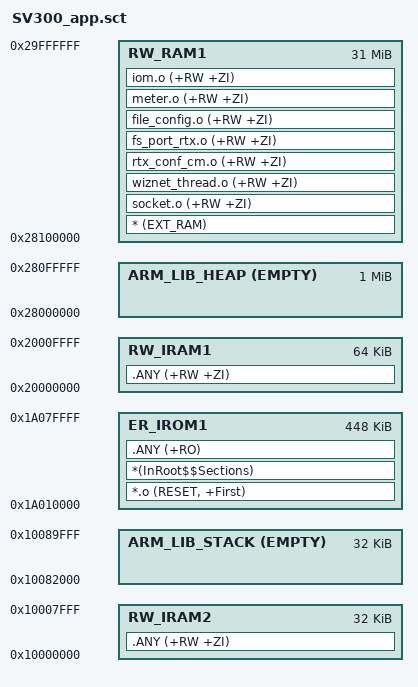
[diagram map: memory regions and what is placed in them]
;******************************************************************
;* LPC4337 linker scatter file (running code from internal FLASH) *
;******************************************************************

LR_IROM1 0x1A010000 0x70000
{
   ER_IROM1 0x1A010000 0x70000
   {
      *.o (RESET, +First)
      *(InRoot$$Sections)
      .ANY (+RO)
   }
   
   RW_IRAM1 0x20000000 0x10000
   { 
      .ANY (+RW +ZI)
   }
   
   RW_IRAM2 0x10000000 0x8000
   { 
      .ANY (+RW +ZI)
   }

   ARM_LIB_STACK 0x1008A000 EMPTY -0x8000
   {
   }
   
   ARM_LIB_HEAP 0x28000000 EMPTY 0x100000
   {
   }
   
   RW_RAM1 0x28100000 0x1f00000  {
      * (EXT_RAM)
      socket.o (+RW +ZI)
      wiznet_thread.o (+RW +ZI)	   
      rtx_conf_cm.o (+RW +ZI)
      fs_port_rtx.o (+RW +ZI)
      file_config.o (+RW +ZI)
      meter.o (+RW +ZI)
      iom.o (+RW +ZI)
   }
}
